# G32R501 register map
Vendor: Geehy Semiconductor Co., Ltd.; Series: G32R5; File version: 1.0
CPU: CM55 r0p1, little endian, MPU, FPU, double-precision FPU, DSP, VTOR, 4 interrupt priority bits
Registers are 32-bit, read-write, reset 0x0 unless marked. A register's access mark holds for its fields unless they carry their own. Offsets are from the block's base; [hi:lo] are bit positions; {n}, {i} and the like mark numbered series; 'fields as' and 'values as' point back to an identical list.

## CLK — CLK_REGS
Base 0x50020800
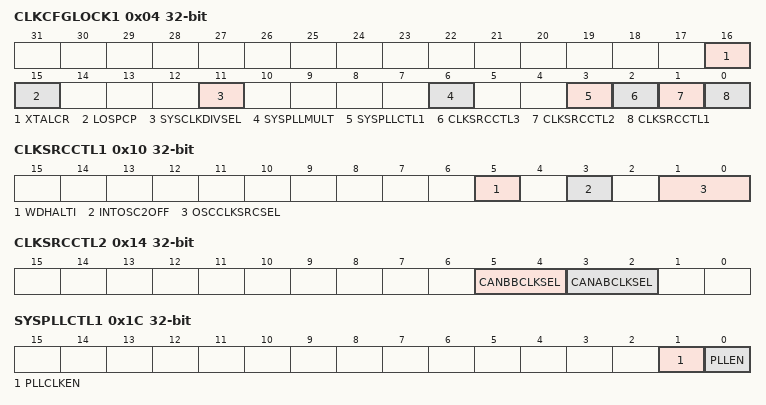
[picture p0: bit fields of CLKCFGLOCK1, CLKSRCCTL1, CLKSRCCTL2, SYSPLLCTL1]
0x04 CLKCFGLOCK1 — Lock bit for CLKCFG registers
  [16] XTALCR — Lock bit for XTALCR register
  [15] LOSPCP — Lock bit for LOSPCP register
  [11] SYSCLKDIVSEL — Lock bit for SYSCLKDIVSEL register
  [6] SYSPLLMULT — Lock bit for SYSPLLMULT register
  [3] SYSPLLCTL1 — Lock bit for SYSPLLCTL1 register
  [2] CLKSRCCTL3 — Lock bit for CLKSRCCTL3 register
  [1] CLKSRCCTL2 — Lock bit for CLKSRCCTL2 register
  [0] CLKSRCCTL1 — Lock bit for CLKSRCCTL1 register
0x10 CLKSRCCTL1 — Clock Source Control register-1
  [5] WDHALTI — Watchdog HALT Mode Ignore Bit
  [3] INTOSC2OFF — Internal Oscillator 2 Off Bit
  [1:0] OSCCLKSRCSEL — Oscillator Clock Source Select Bit
0x14 CLKSRCCTL2 — Clock Source Control register-2
  [5:4] CANBBCLKSEL — CANB Bit-Clock Source Select Bit
  [3:2] CANABCLKSEL — CANA Bit-Clock Source Select Bit
0x18 CLKSRCCTL3 — Clock Source Control register-3
  [2:0] XCLKOUTSEL — XCLKOUT Source Select Bit
0x1C SYSPLLCTL1 — SYSPLL Control register-1
  [1] PLLCLKEN — SYSPLL bypassed or included in the PLLSYSCLK path
  [0] PLLEN — SYSPLL enabled or disabled
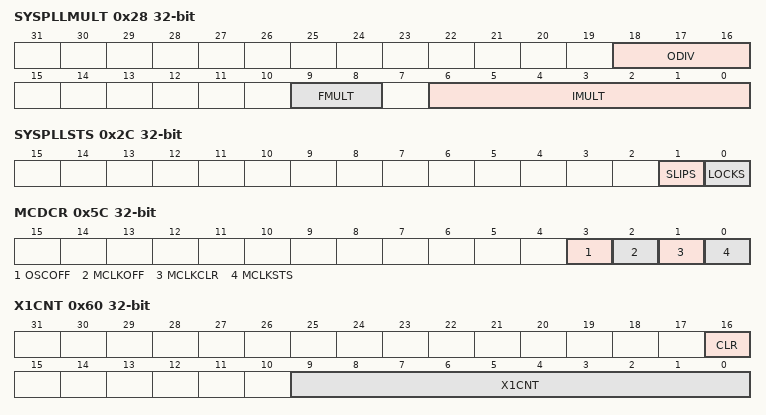
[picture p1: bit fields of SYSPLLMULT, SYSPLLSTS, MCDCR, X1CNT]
0x28 SYSPLLMULT — SYSPLL Multiplier register
  [18:16] ODIV — SYSPLL Output Clock Divider
  [9:8] FMULT — SYSPLL Fractional Multiplier
  [6:0] IMULT — SYSPLL Integer Multiplier
0x2C SYSPLLSTS ro — SYSPLL Status register Go
  [1] SLIPS — SYSPLL Slip Status Bit
  [0] LOCKS — SYSPLL Lock Status Bit
0x44 SYSCLKDIVSEL reset 0x2 — System Clock Divider Select register
  [5:0] PLLSYSCLKDIV — PLLSYSCLK Divide Select
0x50 XCLKOUTDIVSEL reset 0x3 — XCLKOUT Divider Select register
  [1:0] XCLKOUTDIV — XCLKOUT Divide Select
0x58 LOSPCP reset 0x2 — Low Speed Clock Source Prescalar
  [2:0] LSPCLKDIV — These bits configure the low-speed peripheral clock (LSPCLK) rate
0x5C MCDCR access per field — Missing Clock Detect Control Register
  [3] OSCOFF rw — Oscillator Clock Disconnect from MCD Bit
  [2] MCLKOFF rw — Missing Clock Detect Off Bit
  [1] MCLKCLR rw — Missing Clock Clear Bit
  [0] MCLKSTS ro — Missing Clock Status Bit
0x60 X1CNT access per field — 10-bit Counter on X1 Clock
  [16] CLR rw — X1 Counter clear
  [9:0] X1CNT ro — X1 Counter
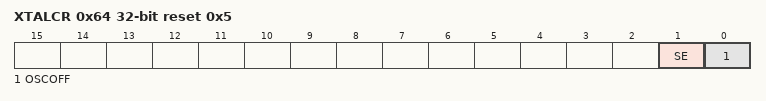
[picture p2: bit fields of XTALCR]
0x64 XTALCR reset 0x5 — XTAL Control Register
  [1] SE — XTAL Oscilator in Single-Ended mode
  [0] OSCOFF — XTAL Oscillator powered-down

## PERIPH — PERIPH_REGS
Base 0x50020C00
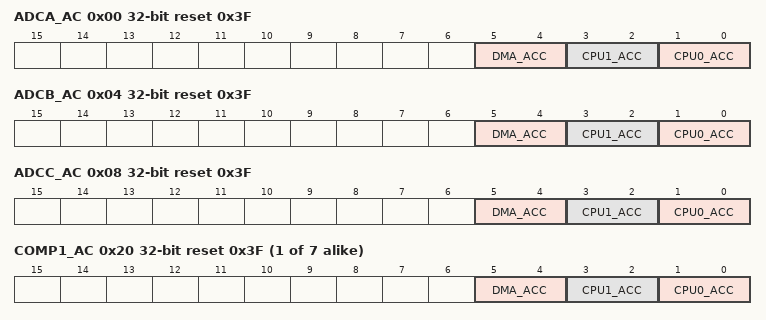
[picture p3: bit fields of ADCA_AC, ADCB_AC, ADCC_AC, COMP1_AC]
0x00 ADCA_AC reset 0x3F — ADCA Master Access Control Register
  [5:4] DMA_ACC — Defines Access control definition for the DMA
  [3:2] CPU1_ACC — Defines Access control definition for the CPU1
  [1:0] CPU0_ACC — Defines Access control definition for the CPU0
0x04 ADCB_AC reset 0x3F — ADCB Master Access Control Register
  fields as ADCA_AC
0x08 ADCC_AC reset 0x3F — ADCC Master Access Control Register
  fields as ADCA_AC
{0x1C+4i} COMP{i}_AC reset 0x3F (i=1..7) — COMP{i} Master Access Control Register
  fields as ADCA_AC
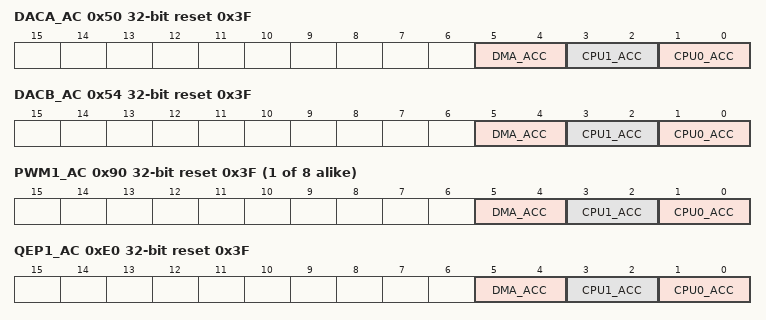
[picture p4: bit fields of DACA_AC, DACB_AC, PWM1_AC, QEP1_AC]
0x50 DACA_AC reset 0x3F — DACA Master Access Control Register
  fields as ADCA_AC
0x54 DACB_AC reset 0x3F — DACB Master Access Control Register
  fields as ADCA_AC
{0x8C+4i} PWM{i}_AC reset 0x3F (i=1..8) — PWM{i} Master Access Control Register
  fields as ADCA_AC
0xE0 QEP1_AC reset 0x3F — QEP1 Master Access Control Register
  fields as ADCA_AC
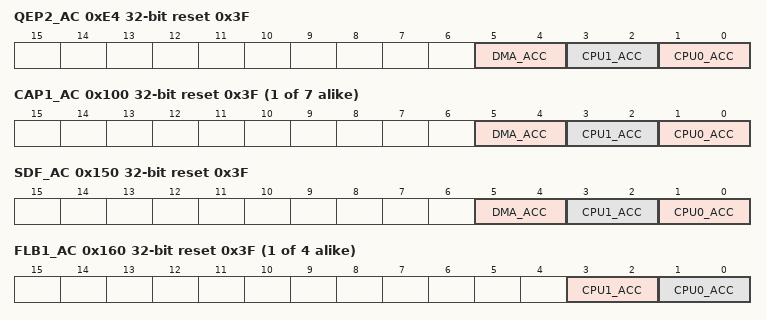
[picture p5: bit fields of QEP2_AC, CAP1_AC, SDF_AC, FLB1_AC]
0xE4 QEP2_AC reset 0x3F — QEP2 Master Access Control Register
  fields as ADCA_AC
{0xFC+4i} CAP{i}_AC reset 0x3F (i=1..7) — CAP{i} Master Access Control Register
  fields as ADCA_AC
0x150 SDF_AC reset 0x3F — SDF Master Access Control Register
  fields as ADCA_AC
{0x15C+4i} FLB{i}_AC reset 0x3F (i=1..4) — FLB{i} Master Access Control Register
  [3:2] CPU1_ACC — Defines Access control definition for the CPU1
  [1:0] CPU0_ACC — Defines Access control definition for the CPU0
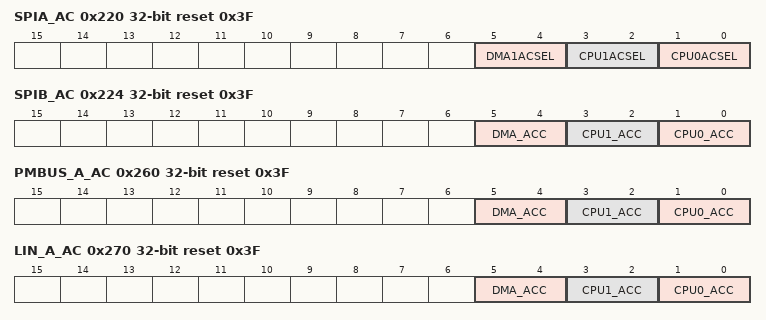
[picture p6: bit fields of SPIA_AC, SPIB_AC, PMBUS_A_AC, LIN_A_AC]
0x220 SPIA_AC reset 0x3F — SPIA Master Access Control Register
  [5:4] DMA1ACSEL — DMA1 access permission Select
  [3:2] CPU1ACSEL — CPU1 access permission Select
  [1:0] CPU0ACSEL — CPU0 access permission Select
0x224 SPIB_AC reset 0x3F — SPIB Master Access Control Register
  fields as ADCA_AC
0x260 PMBUS_A_AC reset 0x3F — PMBUSA Master Access Control Register
  fields as ADCA_AC
0x270 LIN_A_AC reset 0x3F — LINA Master Access Control Register
  fields as ADCA_AC
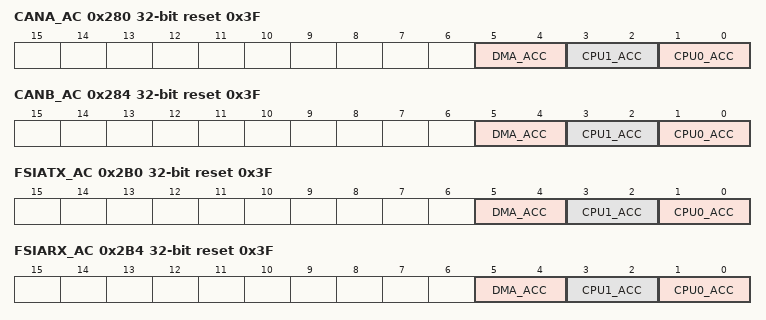
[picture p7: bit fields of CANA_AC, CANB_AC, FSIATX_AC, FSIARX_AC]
0x280 CANA_AC reset 0x3F — CANA Master Access Control Register
  fields as ADCA_AC
0x284 CANB_AC reset 0x3F — CANB Master Access Control Register
  fields as ADCA_AC
0x2B0 FSIATX_AC reset 0x3F — FSIA Master Access Control Register
  fields as ADCA_AC
0x2B4 FSIARX_AC reset 0x3F — FSIB Master Access Control Register
  fields as ADCA_AC
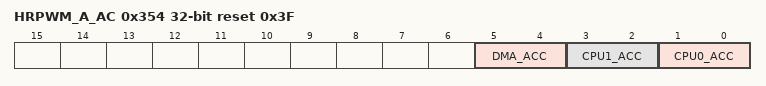
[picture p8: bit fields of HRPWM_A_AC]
0x354 HRPWM_A_AC reset 0x3F — HRPWM Master Access Control Register
  fields as ADCA_AC
0x3FC PERIPH_AC_LOCK — Lock Register to stop Write access to peripheral Access register
  [0] LOCK_AC_WR — Defines Access control definition for the CPU1
